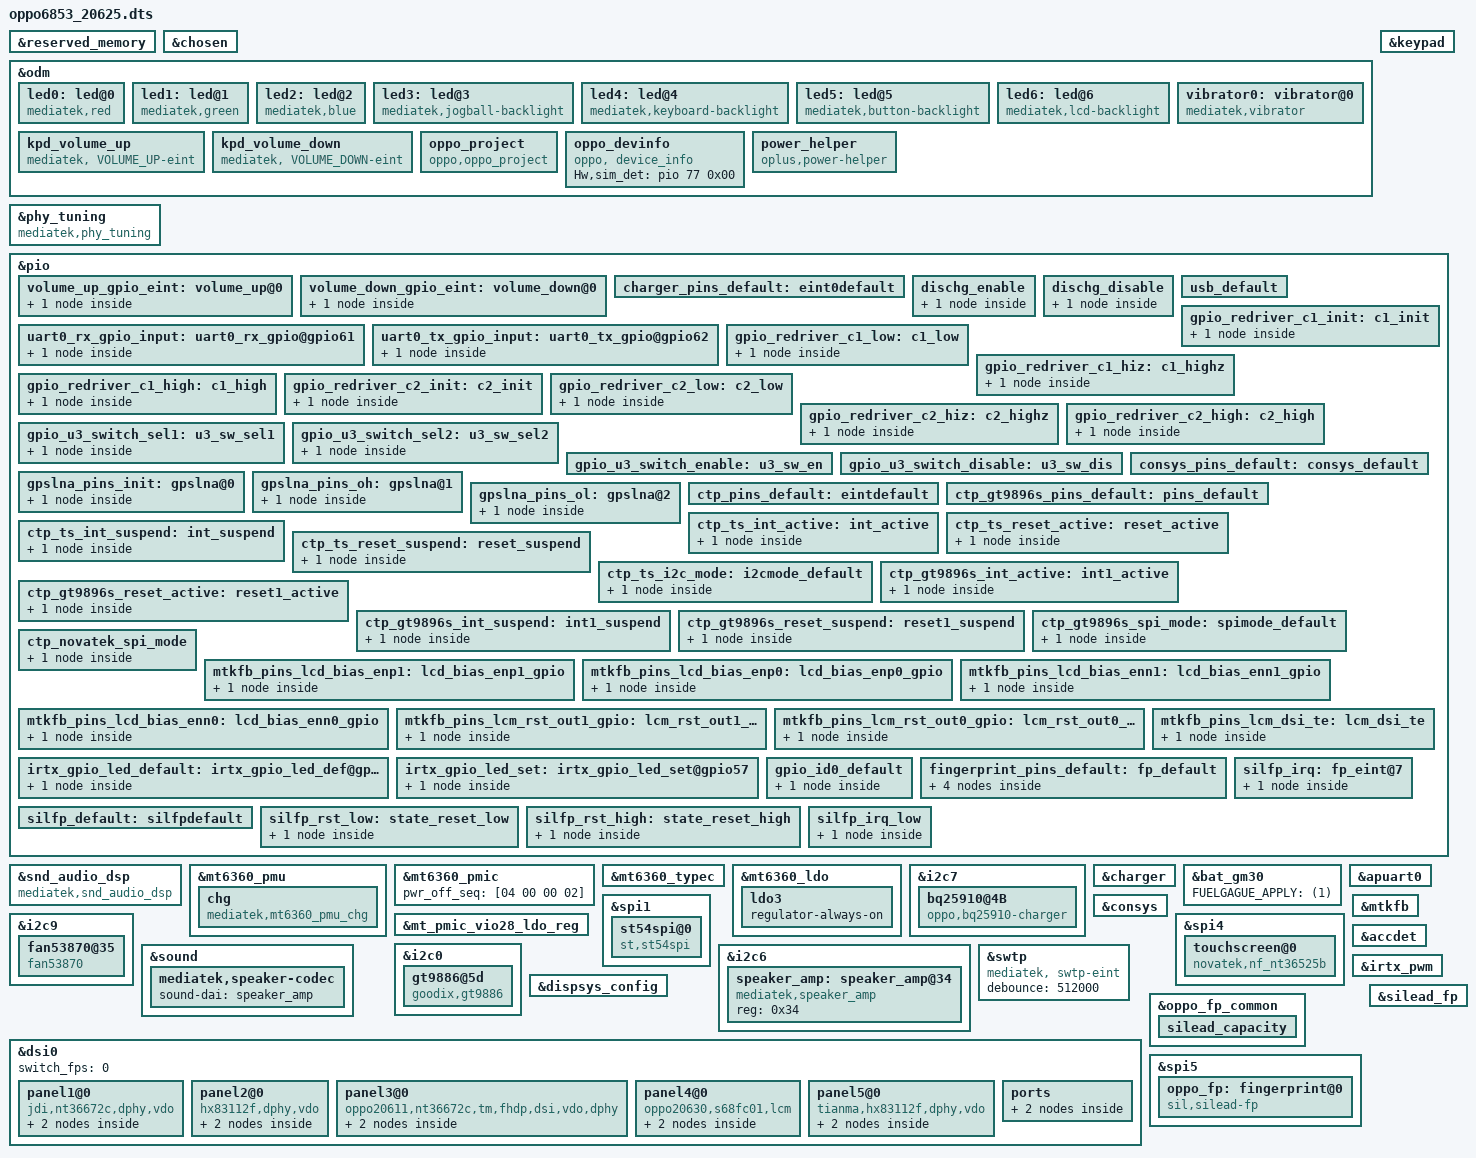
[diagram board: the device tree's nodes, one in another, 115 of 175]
/*
 * Mediatek's mt6853 SoC device tree source
 *
 * Copyright (C) 2016 MediaTek Inc.
 *
 * This program is free software; you can redistribute it and/or modify
 * it under the terms of the GNU General Public License version 2 as
 * published by the Free Software Foundation.
 *
 * This program is distributed in the hope that it will be useful,
 * but WITHOUT ANY WARRANTY; without even the implied warranty of
 * MERCHANTABILITY or FITNESS FOR A PARTICULAR PURPOSE.
 * See http://www.gnu.org/licenses/gpl-2.0.html for more details.
 */
/dts-v1/;
/plugin/;
#include <dt-bindings/interrupt-controller/irq.h>
#include <dt-bindings/interrupt-controller/arm-gic.h>
#include <dt-bindings/pinctrl/mt6853-pinfunc.h>

&reserved_memory {
};

/* chosen */
&chosen {

	atag,videolfb-fb_base_l = <0x7e605000>;
	atag,videolfb-fb_base_h = <0x0>;
	atag,videolfb-islcmfound = <1>;
	atag,videolfb-islcm_inited = <0>;
	atag,videolfb-fps= <6000>; 
	atag,videolfb-vramSize= <0x1be0000>;
	atag,videolfb-lcmname=
		"nt35595_fhd_dsi_cmd_truly_nt50358_drv";
};

&odm {
	led0:led@0 {
		compatible = "mediatek,red";
		led_mode = <0>;
		data = <1>;
		pwm_config = <0 0 0 0 0>;
	};
	led1:led@1 {
		compatible = "mediatek,green";
		led_mode = <0>;
		data = <1>;
		pwm_config = <0 0 0 0 0>;
	};
	led2:led@2 {
		compatible = "mediatek,blue";
		led_mode = <0>;
		data = <1>;
		pwm_config = <0 0 0 0 0>;
	};
	led3:led@3 {
		compatible = "mediatek,jogball-backlight";
		led_mode = <0>;
		data = <1>;
		pwm_config = <0 0 0 0 0>;
	};
	led4:led@4 {
		compatible = "mediatek,keyboard-backlight";
		led_mode = <0>;
		data = <1>;
		pwm_config = <0 0 0 0 0>;
	};
	led5:led@5 {
		compatible = "mediatek,button-backlight";
		led_mode = <0>;
		data = <1>;
		pwm_config = <0 0 0 0 0>;
	};
	led6:led@6 {
		compatible = "mediatek,lcd-backlight";
		led_mode = <4>;
		data = <1>;
		pwm_config = <0 1 0 0 0>;
	};
	vibrator0:vibrator@0 {
		compatible = "mediatek,vibrator";
		//#ifdef VENDOR_EDIT
		/* Xing.Xiong@EXP.BSP.Kernel.Driver.998782, 2017/05/16, Modify for vibrator time less than 9ms */
		vib_timer = <30>;
		vib_limit = <0>;
		//#else
		//vib_timer = <25>;
		//vib_limit = <9>;
		//#endif /* VENDOR_EDIT */
		/* Yunqing.Wang@RM.BSP.Kernel.Driver. 2020/07/13, Modify to 3.0v to enhance vibrator */		
		vib_vol= <11>;
	};

/*VENDOR_EDIT keypad start*/
/*Bin.Li@EXP.BSP.bootloader.bootflow, 2017/05/16, Add volume up and down */
	kpd_volume_up:kpd_volume_up {
		compatible = "mediatek, VOLUME_UP-eint";
		interrupt-parent = <&pio>;
		interrupts = <1 IRQ_TYPE_EDGE_FALLING 1 0>;
		debounce = <32000>;
		status = "okay";
	};

	kpd_volume_down:kpd_volume_down {
		compatible = "mediatek, VOLUME_DOWN-eint";
		interrupt-parent = <&pio>;
		interrupts = <80 IRQ_TYPE_EDGE_FALLING 80 0>;
		debounce = <32000>;
		status = "okay";
	};
/*VENDOR_EDIT keypad end*/

//#ifdef VENDOR_EDIT
/*Bin.Li@EXP.BSP.bootloader.bootflow, 2017/05/15, Add for oppo project */
	oppo_project:oppo_project {
		compatible = "oppo,oppo_project";
	};
	oppo_devinfo:oppo_devinfo {
		compatible = "oppo, device_info";
	};
//#endif /*VENDOR_EDIT*/

};
&phy_tuning {
	compatible = "mediatek,phy_tuning";
	u2_vrt_ref = <7>;
	u2_term_ref = <7>;
	u2_enhance = <3>;

	host_u2_vrt_ref = <6>;
	host_u2_term_ref = <6>;
	host_u2_enhance = <2>;
};
/*VENDOR_EDIT*/
/*Bin.Li@EXP.BSP.bootloader.bootflow, 2017/05/16, Add volume up and down*/
&keypad {
	keypad,volume-up	= <&pio 1 0x00>;
	keypad,volume-down	= <&pio 80 0x00>;
	pinctrl-names = "volume_up_as_int", "volume_down_as_int";
	pinctrl-0 = <&volume_up_gpio_eint>;
	pinctrl-1 = <&volume_down_gpio_eint>;
	status = "okay";
};
&pio {
	volume_up_gpio_eint:volume_up@0{
		pins_cmd_dat {
			pinmux = <PINMUX_GPIO1__FUNC_GPIO1>;
			slew-rate = <0>;  /*direction 0:in, 1:out*/
			input-enable;
		};
	};

	volume_down_gpio_eint:volume_down@0{
		pins_cmd_dat {
			pinmux = <PINMUX_GPIO80__FUNC_GPIO80>;
			slew-rate = <0>;  /*direction 0:in, 1:out*/
			input-enable;
		};
	};
};
/*VENDOR_EDIT*/

&oppo_devinfo {
	Hw,sim_det = <&pio 77 0x00>;
};

&snd_audio_dsp {
	compatible = "mediatek,snd_audio_dsp";
	mtk_dsp_voip = <0x1f 0x1 0xffffffff 0xffffffff 0x30000>;
	mtk_dsp_primary = <0x1f 0x0 0xffffffff 0xffffffff 0x30000>;
	mtk_dsp_offload = <0x0 0x6 0xffffffff 0xffffffff 0x400000>;
	mtk_dsp_deep = <0x5 0x3 0xffffffff 0xffffffff 0x30000>;
	mtk_dsp_playback = <0x1 0x4 0x10 0x14 0x30000>;
	mtk_dsp_music = <0x1 0xffffffff 0xffffffff 0xffffffff 0x0>;
	mtk_dsp_capture1 = <0x1 0xffffffff 0xd 0x13 0x20000>;
	mtk_dsp_a2dp = <0x0 0xffffffff 0xffffffff 0xffffffff 0x40000>;
	mtk_dsp_dataprovider = <0x0 0xffffffff 0xf 0xffffffff 0x30000>;
	mtk_dsp_call_final = <0x1 0x4 0x10 0x14 0x18000>;
	mtk_dsp_fast = <0x5 0x2 0xffffffff 0xffffffff 0x5000>;
	mtk_dsp_ktv = <0x1 0x8 0x12 0xffffffff 0x10000>;
	mtk_dsp_ver = <0x1>;
	swdsp_smartpa_process_enable = <0x1 0x40000>;
};


/* Charging Start */

&mt6360_pmu {
	mt6360,intr_gpio_num = <10>; /* direct defined GPIO num */
	mt6360,intr_gpio = <&pio 10 0x0>;
};

&mt6360_pmic {
	pwr_off_seq = [04 00 00 02];
};

&mt6360_typec {
	mt6360pd,intr_gpio_num = <9>; /* direct defined GPIO num */
	mt6360pd,intr_gpio = <&pio 9 0x0>;
	//mt6360pd,pcb_gpio = <&pio 57 0x0>;
	//mt6360pd,pcb_gpio_num = <57>;
};

&mt6360_pmu {
	chg {
		compatible = "mediatek,mt6360_pmu_chg";
		interrupt-parent = <&mt6360_pmu>;
		interrupts = <4 0>, <6 0>, <7 0>, <9 0>,
				<12 0>, <13 0>, <14 0>, <15 0>,
				<27 0>, <29 0>, <30 0>, <32 0>,
				<35 0>, <40 0>, <48 0>, <60 0>,
				<53 0>;
		interrupt-names = "chg_treg_evt", "chg_mivr_evt",
				"pwr_rdy_evt", "chg_batsysuv_evt",
				"chg_vsysuv_evt", "chg_vsysov_evt",
				"chg_vbatov_evt", "chg_vbusov_evt",
				"chg_tmri", "chg_adpbadi",
				"chg_rvpi",  "chg_aiccmeasl",
				"wdtmri", "pumpx_donei",
				"attachi", "chrdet_ext_evt",
				"hvdcp_det";
		io-channels = <&adc 0>, <&adc 1>, <&adc 3>, <&adc 4>,
				<&adc 5>, <&adc 6>, <&adc 8>, <&adc 10>;
		io-channel-names = "USBID", "VBUSDIV5", "VSYS", "VBAT",
				"IBUS", "IBAT", "TEMP_JC", "TS";
		chg_name = "primary_chg";
		ichg = <2000000>;               /* uA */
		aicr = <500000>;                /* uA */
		mivr = <4400000>;               /* uV */
		cv = <4350000>;                 /* uA */
		ieoc = <150000>;                /* uA */
		safety_timer = <20>;            /* hour */
		ircmp_resistor = <25000>;       /* uohm */
		ircmp_vclamp = <32000>;         /* uV */
		en_te = <1>;
		en_wdt = <1>;
		aicc_once = <1>;
		post_aicc = <1>;
		batoc_notify = <0>;
	};
};

//#ifdef VENDOR_EDIT
//Baoquan.Lai@BSP.CHG.Basic, 2019/09/19, Modify for gpio128
&mt6360_ldo{
	ldo3{
		regulator-always-on;
	};
};
//#endif

&i2c7 {
	bq25910@4B{
		status = "okay";
		compatible = "oppo,bq25910-charger";
		reg = <0x4B>;
		chip-name = "BQ25910";
	};
};

&charger {
io-channels =  <&auxadc 3>,<&auxadc 4>,
		<&auxadc 5>;
	io-channel-names = "auxadc3-chargeric_temp","auxadc4-usb_temp_v_l",
		"auxadc5-usb_temp_v_r";

	pinctrl-names = "default", "dischg_enable", "dischg_disable";
	pinctrl-0 = <&charger_pins_default>;
	pinctrl-1 = <&dischg_enable>;
	pinctrl-2 = <&dischg_disable>;

	//for oppo chg framework:
	qcom,input_current_charger_ma = <2200>;
	qcom,input_current_usb_ma = <500>;
	qcom,input_current_cdp_ma = <1500>;
	qcom,input_current_led_ma = <1200>;
	qcom,input_current_led_ma_high = <1000>;
	qcom,input_current_led_ma_warm = <1500>;
	qcom,input_current_led_ma_normal = <2000>;
	qcom,input_current_led_ma_forcmcc = <500>;
	qcom,input_current_camera_ma = <2000>;
	qcom,input_current_calling_ma = <1500>;
	qcom,qc_input_current_charger_ma = <2000>;


	qcom,iterm_disabled = <0>;
	qcom,iterm_ma = <244>;
	qcom,recharge-mv = <100>;

	qcom,batt_capacity_mah = <5000>;

	qcom,removed_bat_decidegc = <190>;  /* < -19C */

	qcom,cold_bat_decidegc = <20>;  /* -2C ~ 0C */
        qcom,temp_cold_vfloat_mv = <3980>;
        qcom,temp_cold_fastchg_current_ma = <350>;

        qcom,little_cold_bat_decidegc = <0>;    /* 0C ~ 5C */
        qcom,temp_little_cold_vfloat_mv = <4435>;
        qcom,temp_little_cold_fastchg_current_ma_high = <1700>;
        qcom,temp_little_cold_fastchg_current_ma_low = <1400>;
        qcom,temp_little_cold_fastchg_current_ma = <1700>;
        qcom,qc_temp_little_cold_fastchg_current_ma_high = <2350>;
        qcom,qc_temp_little_cold_fastchg_current_ma_low = <1400>;

	qcom,cool_bat_decidegc = <50>;  /* 5C ~ 12C */
        qcom,temp_cool_vfloat_mv = <4435>;
        qcom,temp_cool_fastchg_current_ma_high = <1700>;
        qcom,temp_cool_fastchg_current_ma_low = <1700>;
        qcom,qc_temp_cool_fastchg_current_ma_high = <2450>;
        qcom,qc_temp_cool_fastchg_current_ma_low = <2450>;

        qcom,little_cool_bat_decidegc = <120>;  /* 12C ~ 16C */
        qcom,temp_little_cool_vfloat_mv = <4435>;
        qcom,temp_little_cool_fastchg_current_ma = <1700>;
        qcom,temp_little_cool_fastchg_current_ma_high = <1700>;
	qcom,temp_little_cool_fastchg_current_ma_low = <1700>;
        qcom,qc_temp_little_cool_fastchg_current_ma = <3400>;	
        qcom,qc_temp_little_cool_fastchg_current_ma_high = <3400>;
        qcom,qc_temp_little_cool_fastchg_current_ma_low = <2450>;

        qcom,normal_bat_decidegc = <160>;       /* 16C ~ 45C */
        qcom,temp_normal_fastchg_current_ma = <1700>;
        qcom,temp_normal_vfloat_mv = <4435>;
        qcom,qc_temp_normal_fastchg_current_ma = <3400>;

        qcom,normal_phase1_bat_decidegc = <160>;       /* 16C ~ 22C */
        qcom,temp_normal_phase1_vfloat_mv = <4435>;
        qcom,temp_normal_phase1_fastchg_current_ma = <3400>;

        qcom,normal_phase2_bat_decidegc = <220>;       /* 22C ~ 34C */
        qcom,temp_normal_phase2_vfloat_mv = <4435>;
        qcom,temp_normal_phase2_fastchg_current_ma_high = <3400>;
        qcom,temp_normal_phase2_fastchg_current_ma_low = <3400>;

        qcom,normal_phase3_bat_decidegc = <340>;       /* 34 ~ 37C */
        qcom,temp_normal_phase3_vfloat_mv = <4435>;
        qcom,temp_normal_phase3_fastchg_current_ma_high = <2900>;
        qcom,temp_normal_phase3_fastchg_current_ma_low = <2900>;

        qcom,normal_phase4_bat_decidegc = <370>;       /* 37C ~ 40C */
        qcom,temp_normal_phase4_vfloat_mv = <4435>;
        qcom,temp_normal_phase4_fastchg_current_ma_high = <2600>;
        qcom,temp_normal_phase4_fastchg_current_ma_low = <2600>;

        qcom,normal_phase5_bat_decidegc = <400>;       /* 40C ~ 42C */
        qcom,temp_normal_phase5_vfloat_mv = <4435>;
        qcom,temp_normal_phase5_fastchg_current_ma = <2300>;

        qcom,normal_phase6_bat_decidegc = <420>;       /* 42C ~ 45C */
        qcom,temp_normal_phase6_vfloat_mv = <4435>;
        qcom,temp_normal_phase6_fastchg_current_ma = <1400>;


        qcom,warm_bat_decidegc = <450>;         /* 45C ~ 53C */ /*8pin Bat Vooc project need add 3 degree C*/
        qcom,temp_warm_vfloat_mv = <4130>;
        qcom,temp_warm_fastchg_current_ma = <1400>;
        qcom,temp_warm_fastchg_current_ma_led_on = <500>;
        qcom,qc_temp_warm_fastchg_current_ma = <1400>;

	qcom,hot_bat_decidegc = <530>;  /* > 53C */

	qcom,non_standard_vfloat_mv = <3980>;
	qcom,non_standard_fastchg_current_ma = <512>;

	qcom,short_c_bat_cv_mv = <4330>;
	qcom,short_c_bat_vfloat_mv = <3800>;
	qcom,short_c_bat_fastchg_current_ma = <512>;
	qcom,short_c_bat_vfloat_sw_limit = <3750>;

	qcom,cold_vfloat_sw_limit = <3930>;
	qcom,little_cold_vfloat_sw_limit = <4385>;
	qcom,cool_vfloat_sw_limit = <4385>;
	qcom,little_cool_vfloat_sw_limit = <4385>;
	qcom,normal_vfloat_sw_limit = <4385>;
	qcom,warm_vfloat_sw_limit = <4080>;
	qcom,non_standard_vfloat_sw_limit = <3930>;

	qcom,max_chg_time_sec = <61920>;
	qcom,charger_hv_thr = <10000>;
	qcom,charger_recv_thr = <9700>;
	qcom,charger_lv_thr = <3400>;
	qcom,vbatt_full_thr = <4435>;
	qcom,vbatt_hv_thr = <4500>;

	qcom,vfloat_step_mv = <8>;
	qcom,non_standard_vfloat_over_sw_limit = <3990>;
	qcom,cold_vfloat_over_sw_limit = <3990>;
	qcom,little_cold_vfloat_over_sw_limit = <4445>;
	qcom,cool_vfloat_over_sw_limit = <4445>;
	qcom,little_cool_vfloat_over_sw_limit = <4445>;
	qcom,normal_vfloat_over_sw_limit = <4445>;
	qcom,warm_vfloat_over_sw_limit = <4140>;

	qcom,vbatt_power_off = <3300>;
	qcom,vbatt_soc_1 = <3410>;
	//qcom,vooc_project = <1>;
	qcom,vbatt_num = <1>;
	qcom,new_ui_warning_support;

	qcom,normal_vterm_hw_inc = <18>;
	qcom,non_normal_vterm_hw_inc = <18>;

	qcom,overchg_normal_fastchg_ma = <700>;/*16C~35c*/
	qcom,overchg_temp_warm_decidegc = <350>;
	qcom,overchg_warm_fastchg_ma = <750>;/*35C~40c*/
	qcom,overchg_temp_high_decidegc = <400>;

	qcom,overchg_normal_vfloat_sw_limit = <4450>;
	qcom,overchg_temp_normal_vfloat_mv = <4500>;
	qcom,overchg_normal_vfloat_over_sw_limit = <4500>;

	qcom,default_iterm_ma = <244>;
	qcom,default_temp_normal_fastchg_current_ma = <2200>;
	qcom,default_normal_vfloat_sw_limit = <4385>;
	qcom,default_temp_normal_vfloat_mv = <4435>;
	qcom,default_normal_vfloat_over_sw_limit = <4445>;

	//for control:
	//qcom,suspend_after_full;
	qcom,check_batt_full_by_sw;
	qcom,external_gauge;
	qcom,chg_ctrl_by_calling;
	qcom,chg_ctrl_by_lcd;
	qcom,chg_ctrl_by_camera;
	qcom,sw_vfloat_over_protect_enable;

	//for PD9V or QC9V
	qcom,vbatt_pdqc_to_5v_thr = <3400>;
	qcom,dual_charger_support = <1>;
	qcom,slave_pct = <30>;
	qcom,slave_chg_enable_ma = <2400>;
	qcom,slave_chg_disable_ma = <2200>;

	//for step charger
	qcom,step1_time = <600>;		/*10min*/
	qcom,step1_current_ma = <3400>;		/*3400ma*/
	qcom,step2_time = <900>;		/*10min*/
	qcom,step2_current_ma = <3200>;		/*3100ma*/
	qcom,step3_current_ma = <3000>;		/*2700ma*/

	//GPIO config:
	qcom,dischg-gpio = <&pio 128 0x00>;
};

&bat_gm30 {
	FUELGAGUE_APPLY = <(1)>;
};
//#ifdef VENDOR_EDIT
//laq@PSW.BSP.sensor, 2020/04/26, Add for 20001 als&ps
&mt_pmic_vio28_ldo_reg {
	regulator-name = "vio28";
	regulator-min-microvolt = <3000000>;
	regulator-max-microvolt = <3000000>;
	regulator-enable-ramp-delay = <240>;
};
//#endif /* VENDOR_EDIT */

&pio {
	charger_pins_default: eint0default {
	};
	
	dischg_enable: dischg_enable {
		pins_cmd_dat {
			pinmux = <PINMUX_GPIO128__FUNC_GPIO128>;
			slew-rate = <1>;//0:input direction 1:output direction
			bias-pull-up = <00>;
			output-high;
		};
	};

	dischg_disable: dischg_disable {
		pins_cmd_dat {
			pinmux = <PINMUX_GPIO128__FUNC_GPIO128>;
			slew-rate = <1>;
			bias-pull-down = <00>;
			output-low;
		};
	};

    /*fsa_hs_det_low: fsa_hs_det_low {
        pins_cmd_dat {
            pinmux = <PINMUX_GPIO128__FUNC_GPIO128>;
            slew-rate = <1>;  //direction 0:in, 1:out
            output-low;
        };
    };

    fsa_hs_det_high: fsa_hs_det_high {
        pins_cmd_dat {
            pinmux = <PINMUX_GPIO128__FUNC_GPIO128>;
            slew-rate = <1>;  //direction 0:in, 1:out
            output-high;
        };
    };*/
};

//#ifdef VENDOR_EDIT
//LiYue@BSP.CHG.Basic, 2019/10/02, Add for chargerid
&apuart0 {
	pinctrl-names = "uart0_rx_gpio",
			"uart0_tx_gpio";
	pinctrl-0 = <&uart0_rx_gpio_input>;
	pinctrl-1 = <&uart0_tx_gpio_input>;
	status = "okay";
};

&pio {
	uart0_rx_gpio_input:uart0_rx_gpio@gpio61 {
		pins_cmd_dat {
			pinmux = <PINMUX_GPIO61__FUNC_GPIO61>;
			input-enable;
			slew-rate = <0>;
			bias-disable;
		};
	};
	uart0_tx_gpio_input:uart0_tx_gpio@gpio62 {
		pins_cmd_dat {
			pinmux = <PINMUX_GPIO62__FUNC_GPIO62>;
			input-enable;
			slew-rate = <0>;
			bias-disable;
		};
	};
};

//#endif /* VENDOR_EDIT */

/*#ifdef VENDOE_EDIT*/
/* Shengguang.Zhu@Cam.Drv, 20200518,  sensor porting!*/
&i2c9 {
       status = "okay";
	   fan53870@35 {
               compatible = "fan53870";
               reg = <0x35>;
               ldo1_min_vol = <800000>;  /*uV*/
               ldo1_max_vol = <1504000>;
               ldo1_step_vol = <8000>;
       };
};
/*#endif*/
/* USB SWITCH GPIO start */
&pio {
	usb_default: usb_default {
	};

	gpio_redriver_c1_init: c1_init {
		pins_cmd_dat {
			pinmux = <PINMUX_GPIO41__FUNC_GPIO41>;
			slew-rate = <1>;
			output-low;
		};
	};

	gpio_redriver_c1_low: c1_low {
		pins_cmd_dat {
			pinmux = <PINMUX_GPIO41__FUNC_GPIO41>;
			slew-rate = <1>;
			output-low;
		};
	};

	gpio_redriver_c1_hiz: c1_highz {
		pins_cmd_dat {
			pinmux = <PINMUX_GPIO41__FUNC_GPIO41>;
			slew-rate= <0>;
			bias-disable;
		};
	};

	gpio_redriver_c1_high: c1_high {
		pins_cmd_dat {
			pinmux = <PINMUX_GPIO41__FUNC_GPIO41>;
			slew-rate = <1>;
			output-high;
		};
	};

	gpio_redriver_c2_init: c2_init {
		pins_cmd_dat {
			pinmux = <PINMUX_GPIO40__FUNC_GPIO40>;
			slew-rate = <1>;
			output-low;
		};
	};

	gpio_redriver_c2_low: c2_low {
		pins_cmd_dat {
			pinmux = <PINMUX_GPIO40__FUNC_GPIO40>;
			slew-rate = <1>;
			output-low;
		};
	};

	gpio_redriver_c2_hiz: c2_highz {
		pins_cmd_dat {
			pinmux = <PINMUX_GPIO40__FUNC_GPIO40>;
			slew-rate= <0>;
			bias-disable;
		};
	};

	gpio_redriver_c2_high: c2_high {
		pins_cmd_dat {
			pinmux = <PINMUX_GPIO40__FUNC_GPIO40>;
			slew-rate = <1>;
			output-high;
		};
	};

	gpio_u3_switch_sel1: u3_sw_sel1 {
		pins_cmd_dat {
			pinmux = <PINMUX_GPIO11__FUNC_GPIO11>;
			slew-rate = <1>;
			output-low;
		};
	};

	gpio_u3_switch_sel2: u3_sw_sel2 {
		pins_cmd_dat {
			pinmux = <PINMUX_GPIO11__FUNC_GPIO11>;
			slew-rate = <1>;
			output-high;
		};
	};

	gpio_u3_switch_enable: u3_sw_en {
	};

	gpio_u3_switch_disable: u3_sw_dis {
	};
};

//#ifdef VENDOR_EDIT
//Zhou.Zheng@CN.NFC.Basic.Hardware,2714107,2020/04/13,Add for:5G-B device
//NFC GPIO start
&spi1 {
	st54spi@0 {
		compatible = "st,st54spi";
		reg = <0>;
		spi-max-frequency = <1000000> ;
		gpio-power = <8>;
		gpio-power-std = <&pio 8 0x0>;
		status = "okay";
	};
};
//NFC GPIO end
//#endif /* VENDOR_EDIT */

/* CONSYS GPIO standardization */
&pio {
	consys_pins_default: consys_default {
	};
	gpslna_pins_init: gpslna@0 {
		pins_cmd_dat {
			pinmux = <PINMUX_GPIO87__FUNC_GPIO87>;
			output-low;
		};
	};
	gpslna_pins_oh: gpslna@1 {
		pins_cmd_dat {
			pinmux = <PINMUX_GPIO87__FUNC_GPS_L1_ELNA_EN>;
		};
	};
	gpslna_pins_ol: gpslna@2 {
		pins_cmd_dat {
			pinmux = <PINMUX_GPIO87__FUNC_GPIO87>;
			output-low;
		};
	};
};

&consys {
	pinctrl-names = "default", "gps_lna_state_init",
		"gps_lna_state_oh", "gps_lna_state_ol";
	pinctrl-0 = <&consys_pins_default>;
	pinctrl-1 = <&gpslna_pins_init>;
	pinctrl-2 = <&gpslna_pins_oh>;
	pinctrl-3 = <&gpslna_pins_ol>;
	status = "okay";
};
/* CONSYS end */

//#ifdef VENDOR_EDIT
//#Guoliang.wu@Bsp.Group.Tp, 2020/03/31, Add for Oppo touchpanel dts
/* TOUCH start */
&spi4 {
	status = "okay";

	 touchscreen@0 {
		compatible = "novatek,nf_nt36525b";
		reg = <0>; //Same as CS ID
		chip-name = "NF_NT36525B";
		status = "ok";
		
		spi-max-frequency = <9600000>;
		interrupt-parent = <&pio>;
		interrupts = <14 IRQ_TYPE_EDGE_FALLING 14 0>;
		irq-gpio = <&pio 14 0x2002>;
		reset-gpio = <&pio 33 0>;

		touchpanel,max-num-support = <10>;
		touchpanel,tx-rx-num = <18 32>;
		touchpanel,panel-coords = <720 1600>;
		touchpanel,display-coords = <720 1600>;
		touchpanel,touchmajor-limit = <0 54>;
		pinctrl-names = "default";
		pinctrl-0 = <&ctp_novatek_spi_mode>;
		incell_screen;
		irq_need_dev_resume_ok;
		fw_edge_limit_support;
		black_gesture_support;
		charger_pump_support;
		headset_pump_support;
		esd_handle_support;
		black_gesture_test_support;
		game_switch_support;
		noflash_support;
		lcd_trigger_load_tp_fw_support;
		smart_gesture_support;
		pressure_report_support;
		fw_update_app_support;
		touchpanel,button-type = <4>;
	};
};

&i2c0 {
	clock-frequency = <400000>;
	pinctrl-names = "default", "ts_int_active",
		"ts_reset_active", "ts_int_suspend",
		"ts_reset_suspend", "ts_i2c_mode";
	pinctrl-0 = <&ctp_pins_default>;
	pinctrl-1 = <&ctp_ts_int_active>;
	pinctrl-2 = <&ctp_ts_reset_active>;
	pinctrl-3 = <&ctp_ts_int_suspend>;
	pinctrl-4 = <&ctp_ts_reset_suspend>;
	pinctrl-5 = <&ctp_ts_i2c_mode>;

	gt9886@5d {
		compatible = "goodix,gt9886";
		reg = <0x5d>;
		status = "ok";

		spi-max-frequency = <9600000>;
		interrupt-parent = <&pio>;
		interrupts = <14 IRQ_TYPE_EDGE_FALLING 14 0>;
		irq-gpio = <&pio 14 0x2002>;
		reset-gpio = <&pio 43 0>;

		touchpanel,max-num-support = <10>;
		touchpanel,tx-rx-num = <16 36>;
		touchpanel,panel-coords = <1080 2400>;
		touchpanel,display-coords = <1080 2400>;
		touchpanel,touchmajor-limit = <0 54>;

		pinctrl-names = "default", "suspend";
		pinctrl-0 = <&ctp_gt9896s_int_active &ctp_gt9896s_reset_active &ctp_gt9896s_spi_mode>;
		pinctrl-1 = <&ctp_gt9896s_int_suspend &ctp_gt9896s_reset_suspend>;

		incell_screen;
		fw_edge_limit_support;
		black_gesture_support;
		charger_pump_support;
		headset_pump_support;
		esd_handle_support;
		black_gesture_test_support;
		game_switch_support;
		noflash_support;
		lcd_trigger_load_tp_fw_support;
		smart_gesture_support;
		pressure_report_support;
		fw_update_app_support;
		fw_update_in_probe_with_headfile;

		touchpanel,button-type = <4>;
	};
};

&pio {
	ctp_pins_default: eintdefault {
	};
	ctp_gt9896s_pins_default: pins_default {
	};
	ctp_ts_int_active: int_active {
		pins_cmd_dat {
			pinmux = <PINMUX_GPIO14__FUNC_GPIO14>;
			slew-rate = <0>;
			bias-pull-up = <11>;
		};
	};
	ctp_ts_reset_active: reset_active {
		pins_cmd_dat {
			pinmux = <PINMUX_GPIO43__FUNC_GPIO43>;
			slew-rate = <1>;
			output-high;
		};
	};
	ctp_ts_int_suspend: int_suspend {
		pins_cmd_dat {
			pinmux = <PINMUX_GPIO14__FUNC_GPIO14>;
			slew-rate = <1>;
			output-low;
		};
	};
	ctp_ts_reset_suspend: reset_suspend {
		pins_cmd_dat {
			pinmux = <PINMUX_GPIO43__FUNC_GPIO43>;
			slew-rate = <1>;
			output-low;
		};
	};
	ctp_ts_i2c_mode: i2cmode_default {
		pins_cmd_dat {
			pinmux = <PINMUX_GPIO97__FUNC_SCL0>,
				<PINMUX_GPIO98__FUNC_SDA0>;
		};
	};
	ctp_gt9896s_int_active: int1_active {
		pins_cmd_dat {
			pinmux = <PINMUX_GPIO14__FUNC_GPIO14>;
			slew-rate = <0>;
			bias-pull-up = <11>;
		};
	};
	ctp_gt9896s_reset_active: reset1_active {
		pins_cmd_dat {
			pinmux = <PINMUX_GPIO33__FUNC_GPIO33>;
			slew-rate = <1>;
			output-high;
		};
	};
	ctp_gt9896s_int_suspend: int1_suspend {
		pins_cmd_dat {
			pinmux = <PINMUX_GPIO14__FUNC_GPIO14>;
			slew-rate = <1>;
			output-low;
		};
	};
	ctp_gt9896s_reset_suspend: reset1_suspend {
		pins_cmd_dat {
			pinmux = <PINMUX_GPIO33__FUNC_GPIO33>;
			slew-rate = <1>;
			output-low;
		};
	};
	ctp_gt9896s_spi_mode: spimode_default {
		pins_cmd_dat {
			pinmux = <PINMUX_GPIO12__FUNC_SPI4_MI>,
				<PINMUX_GPIO13__FUNC_SPI4_MO>,
				<PINMUX_GPIO97__FUNC_SPI4_CLK>,
				<PINMUX_GPIO98__FUNC_SPI4_CSB>;
			drive-strength = <4>;
		};
	};

	
	
};
&pio {
	ctp_novatek_spi_mode:ctp_novatek_spi_mode{
		pins_cmd_dat {
			pinmux = <PINMUX_GPIO12__FUNC_SPI4_MI>,
				<PINMUX_GPIO13__FUNC_SPI4_MO>,
				<PINMUX_GPIO97__FUNC_SPI4_CLK>,
				<PINMUX_GPIO98__FUNC_SPI4_CSB>;
			drive-strength = <4>;
		};	
	};
};
/* TOUCH end */
//#endif /* VENDOR_EDIT */

/* #ifdef VENDOR_EDIT */
/* Hefeng.Wu@RM.MM.AudioDriver.Platform, 2020/06/05, add for project compatible */
&sound {
	mediatek,speaker-codec {
		sound-dai = <&speaker_amp>;
	};
};

&i2c6 {
	speaker_amp: speaker_amp@34 {
		compatible = "mediatek,speaker_amp";
		#sound-dai-cells = <0>;
		reg = <0x34>;
		status = "okay";
	};
};
/* #endif VENDOR_EDIT */

//#ifdef VENDOR_EDIT
//Anhui.Sun@PSW.NW.RF, 2018/12/19, Add for SWTP - RF cable detection
&swtp {
    compatible = "mediatek, swtp-eint";
    debounce = <512000>;
};
//#endif  /*VENDOR_EDIT*/
#include "cust_mt6853_camera_20625.dtsi"
#include <oppo6853_20625/cust.dtsi>
/* DISPSYS GPIO standardization */

#ifndef CONFIG_FPGA_EARLY_PORTING
&pio {
	mtkfb_pins_lcd_bias_enp1: lcd_bias_enp1_gpio {
		pins_cmd_dat {
			pinmux = <PINMUX_GPIO137__FUNC_GPIO137>;
			slew-rate = <1>;
			output-high;
		};
	};

	mtkfb_pins_lcd_bias_enp0: lcd_bias_enp0_gpio {
		pins_cmd_dat {
			pinmux = <PINMUX_GPIO137__FUNC_GPIO137>;
			slew-rate = <1>;
			output-low;
		};
	};

	mtkfb_pins_lcd_bias_enn1: lcd_bias_enn1_gpio {
		pins_cmd_dat {
			pinmux = <PINMUX_GPIO138__FUNC_GPIO138>;
			slew-rate = <1>;
			output-high;
		};
	};

	mtkfb_pins_lcd_bias_enn0: lcd_bias_enn0_gpio {
		pins_cmd_dat {
			pinmux = <PINMUX_GPIO138__FUNC_GPIO138>;
			slew-rate = <1>;
			output-low;
		};
	};

	mtkfb_pins_lcm_rst_out1_gpio: lcm_rst_out1_gpio {
		pins_cmd_dat {
			pinmux = <PINMUX_GPIO86__FUNC_GPIO86>;
			slew-rate = <1>;
			output-high;
		};
	};

	mtkfb_pins_lcm_rst_out0_gpio: lcm_rst_out0_gpio {
		pins_cmd_dat {
			pinmux = <PINMUX_GPIO86__FUNC_GPIO86>;
			slew-rate = <1>;
			output-low;
		};
	};
	mtkfb_pins_lcm_dsi_te: lcm_dsi_te {
		pins_cmd_dat {
			pinmux = <PINMUX_GPIO84__FUNC_DSI_TE>;
		};
	};
};

&dispsys_config {
	pinctrl-names =
		"lcm_rst_out1_gpio", "lcm_rst_out0_gpio",
		"mode_te_te";
	pinctrl-0 = <&mtkfb_pins_lcm_rst_out1_gpio>;
	pinctrl-1 = <&mtkfb_pins_lcm_rst_out0_gpio>;
	pinctrl-2 = <&mtkfb_pins_lcm_dsi_te>;
	status = "okay";
};

&dsi0 {
	status = "okay";
	#address-cells = <1>;
	#size-cells = <0>;
	switch_fps = <0>;
	panel1@0 {
		compatible = "jdi,nt36672c,dphy,vdo";
                reg = <0>;
		lcd-1p8-gpios = <&pio 136 0>;
                pm-enable-gpios = <&pio 41 0>;
                reset-gpios = <&pio 86 0>;
                bias-gpios = <&pio 137 0>,
                        <&pio 138 0>; 
		pinctrl-names = "default";
		port {
			panel_in1: endpoint {
				remote-endpoint = <&dsi_out>;
			};
		};
	};
	panel2@0 {
		compatible = "hx83112f,dphy,vdo";
                reg = <1>;
                pm-enable-gpios = <&pio 84 0>;
                reset-gpios = <&pio 86 0>;
                ldo3-supply = <&mt_pmic_vmc_ldo_reg>;
                ldo5-supply = <&mt_pmic_vmch_ldo_reg>;   
		pinctrl-names = "default";
		port {
			panel_in2: endpoint {
				remote-endpoint = <&dsi_out>;
			};
		};
	};
	panel3@0 {
		compatible = "oppo20611,nt36672c,tm,fhdp,dsi,vdo,dphy";
		reg = <2>;
		lcd-1p8-gpios = <&pio 136 0>;
		pm-enable-gpios = <&pio 41 0>;
		reset-gpios = <&pio 86 0>;
		bias-gpios = <&pio 137 0>,
			<&pio 138 0>;
		pinctrl-names = "default";
		port {
			panel_in3: endpoint {
				remote-endpoint = <&dsi_out>;
		};
			};
	};
	panel4@0 {
		compatible = "oppo20630,s68fc01,lcm";
		reg = <3>;
		pm-enable-gpios = <&pio 84 0>;
                reset-gpios = <&pio 86 0>;
                ldo3-supply = <&mt_pmic_vmc_ldo_reg>;
                ldo5-supply = <&mt_pmic_vmch_ldo_reg>;
		pinctrl-names = "default";
		port {
			panel_in4: endpoint {
				remote-endpoint = <&dsi_out>;
		};
			};
	};
        panel5@0 {
                compatible = "tianma,hx83112f,dphy,vdo";
                reg = <4>;
                pm-enable-gpios = <&pio 41 0>;
                reset-gpios = <&pio 86 0>;
                bias-gpios = <&pio 137 0>,
                        <&pio 138 0>;
                pinctrl-names = "default";
                port {
                        panel_in5: endpoint {
                                remote-endpoint = <&dsi_out>;
                };
                        };
        };
	ports {
		port {
			dsi_out: endpoint {
				remote-endpoint = <&panel_in1>;
			};
		};
	};
};

&mtkfb {
	pinctrl-names = "lcd_bias_enp1_gpio", "lcd_bias_enp0_gpio",
		"lcd_bias_enn1_gpio", "lcd_bias_enn0_gpio",
		"lcm_rst_out1_gpio", "lcm_rst_out0_gpio",
		"mode_te_te";
	pinctrl-0 = <&mtkfb_pins_lcd_bias_enp1>;
	pinctrl-1 = <&mtkfb_pins_lcd_bias_enp0>;
	pinctrl-2 = <&mtkfb_pins_lcd_bias_enn1>;
	pinctrl-3 = <&mtkfb_pins_lcd_bias_enn0>;
	pinctrl-4 = <&mtkfb_pins_lcm_rst_out1_gpio>;
	pinctrl-5 = <&mtkfb_pins_lcm_rst_out0_gpio>;
	pinctrl-6 = <&mtkfb_pins_lcm_dsi_te>;
	status = "okay";
};

/* accdet start */
&accdet {
	/* accdet micbias voltage: 0x09:2.85v 0x08:2.8v 0x07,
	 * 2.7v;0x05,2.5v;0x02,1.9v
	 */
	accdet-mic-vol = <8>;
	/* accdet pwm_width, pwm_thresh, fall_delay, rise_delay
	 * debounce0, debounce1, debounce3, debounce4
	 * eint pwm_width, eint pwm_thresh
	 * eint deb(debounce0, debounce1, debounce2, debounce3), inv_debounce
	 */

        //#ifdef VENDOR_EDIT
        /*Wenyang.Fan@PSW.MM.AudioDriver.HeadsetDet,2020/3/11,Modify for bug 2843494*/
        headset-mode-setting = <0x500 0x500 1 0x1f0
                                0x2000 0x800 0x2000 0x44
                                0x0 0x7
                                0x5 0x9 0x9 0xd 0xe>;
        //#else /* VENDOR_EDIT */
        /*headset-mode-setting = <0x500 0x500 1 0x1f0
         *                      0x800 0x800 0x20 0x44
         *                      0x4 0x1
         *                      0x5 0x3 0x3 0x5 0xe>;
         */
         //#endif /* VENDOR_EDIT */

	accdet-plugout-debounce = <1>;
	/*1:ACC mode, 2:low cost without in bias, 6:low cost with in bias*/
	accdet-mic-mode = <2>;
	/*0--MD_MAX--UP_MAX--DW_MAX*/
	//#ifdef VENDOR_EDIT
	//Yongzhi.Zhang@PSW.MM.AudioDriver.HeadsetDet, 2017/14/14, Modify for support headset key
	headset-three-key-threshold = <0 82 170 306>;
	//#else /* VENDOR_EDIT */
	//headset-three-key-threshold = <0 80 220 400>;
	//#endif /* VENDOR_EDIT */
	headset-three-key-threshold-CDD = <0 121 192 600>;
	/*0--MD_MAX--VOICE_MAX--UP_MAX--DW_MAX*/
	headset-four-key-threshold = <0 58 121 192 400>;

        //#ifdef VENDOR_EDIT
        //An.Hu@PSW.MM.AudioDriver.HeadsetDet,2020/02/07,Modify for support headset hpimpendence test
	/* moisture HW mode config start. Enable moisture detection or not
	 * default use HW mode for moisture detection
	 */
	moisture_detect_enable = <1>;
        //#endif /* VENDOR_EDIT */
	/* select VTH to 2v and 500k, use internal resitance */
	eint_use_ext_res = <0>;
        //#ifdef VENDOR_EDIT
        //An.Hu@PSW.MM.AudioDriver.HeadsetDet,2020/02/07,Modify for support headset hpimpendence test
	/* enable eint detection mode, if moisture detection enable
	 * eint_detect_mode = moisture_detect_mode;otherwise, select
	 * eint_detect_mode = 4 as DEFAULT
	 */
	eint_detect_mode = <5>;
	/* enable moisture detection mode, if moisture detection enable
	 * eint_detect_mode = moisture_detect_mode
	 */
	moisture_detect_mode = <5>;
	/* select 0: 2.8V; 1: 2.4V; 2: 2V; 3: VTH=MVTH(VTH2) */
	moisture_comp_vth = <2>;
	/* vref2 voltage for different water impedance */
	moisture_comp_vref2 = <2>;
	/* moisture HW mode config end */

	/* moisture SW mode config start, use external resister or not.
	 * DEFAULT NOT NEED
	 */
	moisture_use_ext_res = <0>;
	/* moisture external resister ohm, SW mode by auxadc */
	moisture-external-r = <2000000>;
	/* moisture internal resister ohm, SW mode by auxadc */
	moisture-internal-r = <47000>;
	/* moisture of water resister ohm, SW mode by auxadc*/
	moisture-water-r = <10000>;
	/* moisture SW mode config end */
        //#endif /* VENDOR_EDIT */
	status = "okay";
};
/* accdet end */

/* IRTX GPIO Start */
&irtx_pwm {
	pinctrl-names = "irtx_gpio_led_default", "irtx_gpio_led_set";
	pinctrl-0 = <&irtx_gpio_led_default>;
	pinctrl-1 = <&irtx_gpio_led_set>;
	status = "okay";
};

&pio {
	/* IRTX GPIO Settings -Start */
	/* default: GPIO0, output, high */
	irtx_gpio_led_default:irtx_gpio_led_def@gpio57 {
		pins_cmd_dat {
			pinmux = <PINMUX_GPIO57__FUNC_GPIO57>;
			slew-rate = <1>;
			bias-disable;
			output-low;
			input-schmitt-enable = <0>;
		};
	};

	irtx_gpio_led_set:irtx_gpio_led_set@gpio57 {
		pins_cmd_dat {
			pinmux = <PINMUX_GPIO57__FUNC_PWM_3>;
			slew-rate = <1>;
			output-high;
		};
	};
}; /* IRTX GPIO Settings -End */

/* FINGERPRINT start */
//ifdef VENDOR_EDIT
//Jiaqi.Wu@BSP.Fingerprint.Basic, 2018/09/10, add for fingerprint
&oppo_fp_common {
    oppo,fp_gpio = <41>;
    oppo,fp_gpio_id = <&pio 41 0x0>;
    pinctrl-names = "default";
    pinctrl-0 = <&gpio_id0_default>;
	silead_capacity {
		oppo,fp-id =  <0>; /* fp id mapping table */
		vendor-chip = <18>; /* please refer to the struct fp_vendor_t in oppo_fp_commmon.n */
		eng-menu = "-1,-1"; /* represents SNR, inclination test item in engineer menu, and 0/1 means off/on */
		chip-name = "S_6150";  /* /proc/fp_id, will be displayed in engineer menu  */
	};
};

&pio{
	gpio_id0_default: gpio_id0_default {
		pins_cmd_dat {
			pinmux = <PINMUX_GPIO41__FUNC_GPIO41>;
			slew-rate = <0>;
			bias-pull-up = <00>;
			input-enable;
		};
	};
};
//ifdef VENDOR_EDIT
//Rui.Tuo@RM.BSP.Fingerprint.Basic 2020/06/17 add for silead fingerprint driver start
/* silead GPIO standardization */
&spi5 {
#address-cells = <1>;
#size-cells = <0>;
status = "okay";
oppo_fp: fingerprint@0 {
		 compatible = "sil,silead-fp";
		 reg = <0>;
		 spi-max-frequency = <8000000>;
		 spi-id = <5>;
		 spi-irq = <39>;
		 spi-reg = <11019000>;
		 status = "okay";
	 };
};

&pio {
    fingerprint_pins_default: fp_default {
	    pins_cmd_dat {
		    pinmux = <PINMUX_GPIO29__FUNC_SPI5_CSB>;
		    slew-rate = <1>;
		    bias-pull-up = <00>;
		};
	    pins_cmd1_dat {
		    pinmux = <PINMUX_GPIO28__FUNC_SPI5_CLK>;
		    slew-rate = <1>;
		    bias-pull-down = <00>;
		};
	    pins_cmd2_dat {
		    pinmux = <PINMUX_GPIO31__FUNC_SPI5_MI>;
		    slew-rate = <0>;
		    bias-pull-down = <00>;
		};
	    pins_cmd3_dat {
		    pinmux = <PINMUX_GPIO30__FUNC_SPI5_MO>;
		    slew-rate = <1>;
		    bias-pull-down = <00>;
		};
	};
};

&silead_fp {
	pinctrl-names = "default", "rst-low", "rst-high",
	                "irq-init", "spi-default", "irq_low";
	pinctrl-0 = <&silfp_default>;
	pinctrl-1 = <&silfp_rst_low>;
	pinctrl-2 = <&silfp_rst_high>;
	pinctrl-3 = <&silfp_irq>;
	pinctrl-4 = <&fingerprint_pins_default>;
    pinctrl-5 = <&silfp_irq_low>;

	status = "okay";
};

&pio {
	silfp_default: silfpdefault {
	};
	silfp_rst_low: state_reset_low {
		pins_cmd_dat {
			pinmux = <PINMUX_GPIO6__FUNC_GPIO6>;
			slew-rate = <1>;
			output-low;
		};
	};
	silfp_rst_high: state_reset_high {
		pins_cmd_dat {
			pinmux = <PINMUX_GPIO6__FUNC_GPIO6>;
			slew-rate = <1>;
			output-high;
		};
	};
	silfp_irq: fp_eint@7 {
		pins_cmd_dat {
			pinmux = <PINMUX_GPIO7__FUNC_GPIO7>;
			slew-rate = <0>;
			bias-pull-down = <00>;
		};
	};
	silfp_irq_low: silfp_irq_low {
		pins_cmd_dat {
			pinmux = <PINMUX_GPIO7__FUNC_GPIO7>;
			slew-rate = <1>;
			output-low;
		};
	};

};
//#endif

&odm{
        power_helper {
                compatible = "oplus,power-helper";
        };
};

#endif
/*End of this file, DO NOT ADD ANYTHING HERE*/

